# iostr710 register map
Registers are 16-bit, access not given, no defined reset value unless marked. A register's access mark holds for its fields unless they carry their own. Addresses are absolute; registers are grouped by the start of their names; [hi:lo] are bit positions; {n}, {i} and the like mark numbered series; 'fields as' and 'values as' point back to an identical list.

## RTC
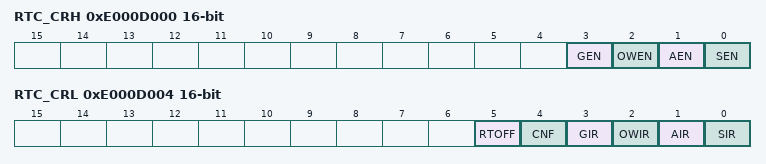
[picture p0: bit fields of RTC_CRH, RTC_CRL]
0xE000D000 RTC_CRH
  [3] GEN, [2] OWEN, [1] AEN, [0] SEN
0xE000D004 RTC_CRL
  [5] RTOFF, [4] CNF, [3] GIR, [2] OWIR, [1] AIR, [0] SIR
0xE000D008 RTC_PRLH
  [3:0] PRSL
0xE000D00C RTC_PRLL
0xE000D010 RTC_DIVH
  [3:0] RTCDIV
0xE000D014 RTC_DIVL
0xE000D018 RTC_CNTH
0xE000D01C RTC_CNTL
0xE000D020 RTC_ALRH
0xE000D024 RTC_ALRL

## WDG
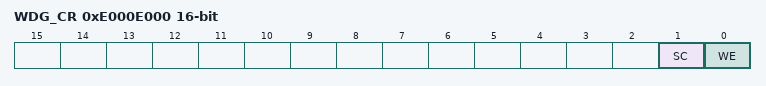
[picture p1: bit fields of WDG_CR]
0xE000E000 WDG_CR
  [1] SC, [0] WE
0xE000E004 WDG_PR
  [7:0] PR
0xE000E008 WDG_VR
0xE000E00C WDG_CNT
0xE000E010 WDG_SR
  [0] EC
0xE000E014 WDG_MR
  [0] ECM
0xE000E018 WDG_KR

## TIM0
0xE0009000 TIM0_ICAR
0xE0009004 TIM0_ICBR
0xE0009008 TIM0_OCAR
0xE000900C TIM0_OCBR
0xE0009010 TIM0_CNTR
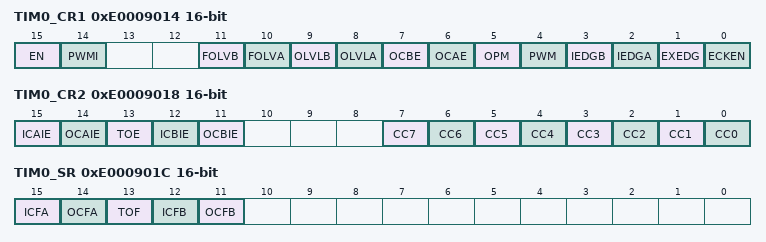
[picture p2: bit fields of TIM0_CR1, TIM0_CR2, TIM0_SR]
0xE0009014 TIM0_CR1
  [15] EN, [14] PWMI, [11] FOLVB, [10] FOLVA, [9] OLVLB, [8] OLVLA, [7] OCBE, [6] OCAE, [5] OPM, [4] PWM, [3] IEDGB, [2] IEDGA, [1] EXEDG, [0] ECKEN
0xE0009018 TIM0_CR2
  [15] ICAIE, [14] OCAIE, [13] TOE, [12] ICBIE, [11] OCBIE, [n] CC{n} (n=0..7)
0xE000901C TIM0_SR
  [15] ICFA, [14] OCFA, [13] TOF, [12] ICFB, [11] OCFB

## TIM1
0xE000A000 TIM1_ICAR
0xE000A004 TIM1_ICBR
0xE000A008 TIM1_OCAR
0xE000A00C TIM1_OCBR
0xE000A010 TIM1_CNTR
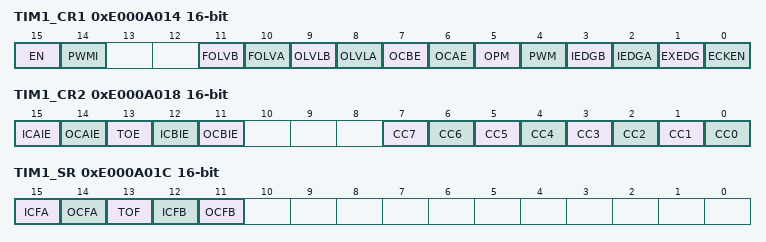
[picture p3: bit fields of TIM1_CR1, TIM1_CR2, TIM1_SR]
0xE000A014 TIM1_CR1
  [15] EN, [14] PWMI, [11] FOLVB, [10] FOLVA, [9] OLVLB, [8] OLVLA, [7] OCBE, [6] OCAE, [5] OPM, [4] PWM, [3] IEDGB, [2] IEDGA, [1] EXEDG, [0] ECKEN
0xE000A018 TIM1_CR2
  [15] ICAIE, [14] OCAIE, [13] TOE, [12] ICBIE, [11] OCBIE, [n] CC{n} (n=0..7)
0xE000A01C TIM1_SR
  [15] ICFA, [14] OCFA, [13] TOF, [12] ICFB, [11] OCFB

## TIM2
0xE000B000 TIM2_ICAR
0xE000B004 TIM2_ICBR
0xE000B008 TIM2_OCAR
0xE000B00C TIM2_OCBR
0xE000B010 TIM2_CNTR
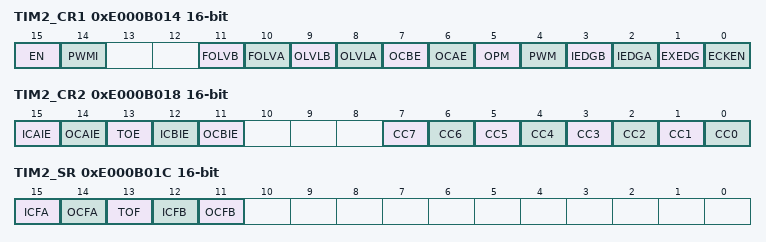
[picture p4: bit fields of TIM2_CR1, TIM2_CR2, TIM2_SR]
0xE000B014 TIM2_CR1
  [15] EN, [14] PWMI, [11] FOLVB, [10] FOLVA, [9] OLVLB, [8] OLVLA, [7] OCBE, [6] OCAE, [5] OPM, [4] PWM, [3] IEDGB, [2] IEDGA, [1] EXEDG, [0] ECKEN
0xE000B018 TIM2_CR2
  [15] ICAIE, [14] OCAIE, [13] TOE, [12] ICBIE, [11] OCBIE, [n] CC{n} (n=0..7)
0xE000B01C TIM2_SR
  [15] ICFA, [14] OCFA, [13] TOF, [12] ICFB, [11] OCFB

## TIM3
0xE000C000 TIM3_ICAR
0xE000C004 TIM3_ICBR
0xE000C008 TIM3_OCAR
0xE000C00C TIM3_OCBR
0xE000C010 TIM3_CNTR
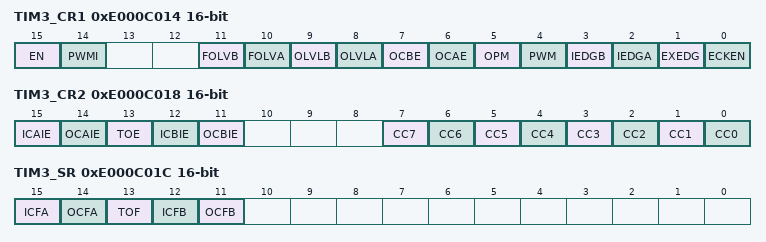
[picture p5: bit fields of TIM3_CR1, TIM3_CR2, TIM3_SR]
0xE000C014 TIM3_CR1
  [15] EN, [14] PWMI, [11] FOLVB, [10] FOLVA, [9] OLVLB, [8] OLVLA, [7] OCBE, [6] OCAE, [5] OPM, [4] PWM, [3] IEDGB, [2] IEDGA, [1] EXEDG, [0] ECKEN
0xE000C018 TIM3_CR2
  [15] ICAIE, [14] OCAIE, [13] TOE, [12] ICBIE, [11] OCBIE, [n] CC{n} (n=0..7)
0xE000C01C TIM3_SR
  [15] ICFA, [14] OCFA, [13] TOF, [12] ICFB, [11] OCFB

## CAN
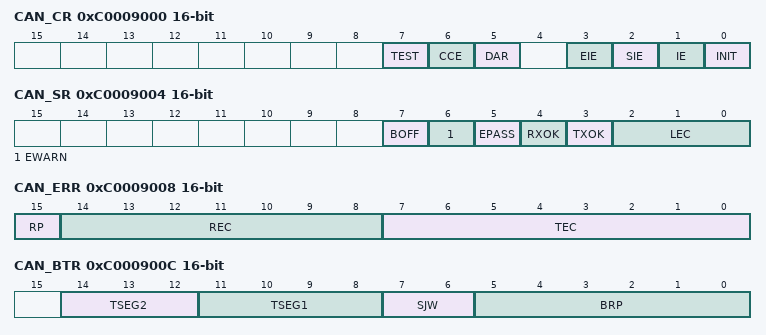
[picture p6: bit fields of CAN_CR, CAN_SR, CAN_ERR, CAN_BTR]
0xC0009000 CAN_CR
  [7] TEST, [6] CCE, [5] DAR, [3] EIE, [2] SIE, [1] IE, [0] INIT
0xC0009004 CAN_SR
  [7] BOFF, [6] EWARN, [5] EPASS, [4] RXOK, [3] TXOK, [2:0] LEC
0xC0009008 CAN_ERR
  [15] RP, [14:8] REC, [7:0] TEC
0xC000900C CAN_BTR
  [14:12] TSEG2, [11:8] TSEG1, [7:6] SJW, [5:0] BRP
0xC0009010 CAN_IDR
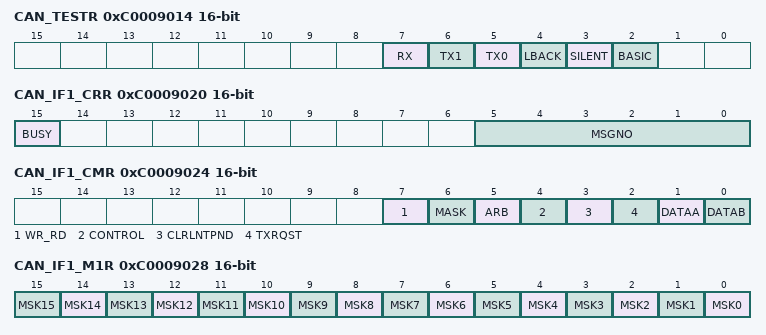
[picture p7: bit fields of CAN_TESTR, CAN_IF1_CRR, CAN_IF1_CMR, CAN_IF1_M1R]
0xC0009014 CAN_TESTR
  [7] RX, [6] TX1, [5] TX0, [4] LBACK, [3] SILENT, [2] BASIC
0xC0009018 CAN_BRPR
  [3:0] BRPE
0xC0009020 CAN_IF1_CRR
  [15] BUSY, [5:0] MSGNO
0xC0009024 CAN_IF1_CMR
  [7] WR_RD, [6] MASK, [5] ARB, [4] CONTROL, [3] CLRLNTPND, [2] TXRQST, [1] DATAA, [0] DATAB
0xC0009028 CAN_IF1_M1R
  [n] MSK{n} (n=0..15)
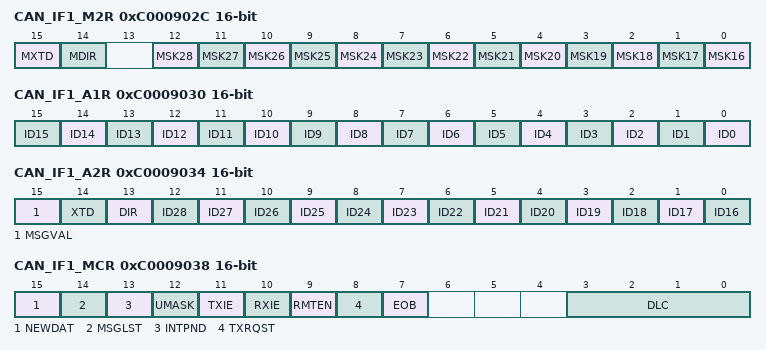
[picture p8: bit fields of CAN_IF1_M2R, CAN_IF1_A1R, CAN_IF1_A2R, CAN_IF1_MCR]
0xC000902C CAN_IF1_M2R
  [15] MXTD, [14] MDIR, [n-16] MSK{n} (n=16..28)
0xC0009030 CAN_IF1_A1R
  [n] ID{n} (n=0..15)
0xC0009034 CAN_IF1_A2R
  [15] MSGVAL, [14] XTD, [13] DIR, [n-16] ID{n} (n=16..28)
0xC0009038 CAN_IF1_MCR
  [15] NEWDAT, [14] MSGLST, [13] INTPND, [12] UMASK, [11] TXIE, [10] RXIE, [9] RMTEN, [8] TXRQST, [7] EOB, [3:0] DLC
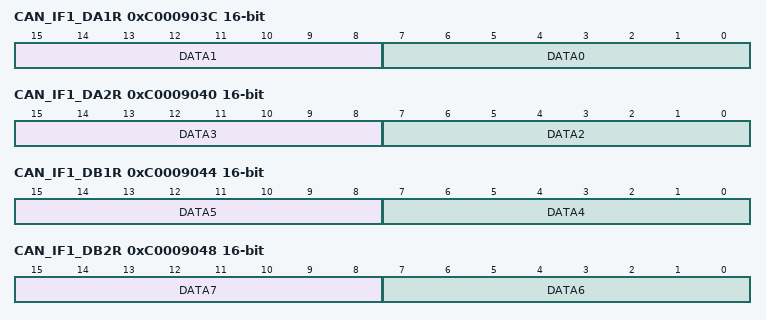
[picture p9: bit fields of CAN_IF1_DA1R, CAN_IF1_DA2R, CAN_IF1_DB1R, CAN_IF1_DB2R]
0xC000903C CAN_IF1_DA1R
  [15:8] DATA1, [7:0] DATA0
0xC0009040 CAN_IF1_DA2R
  [15:8] DATA3, [7:0] DATA2
0xC0009044 CAN_IF1_DB1R
  [15:8] DATA5, [7:0] DATA4
0xC0009048 CAN_IF1_DB2R
  [15:8] DATA7, [7:0] DATA6
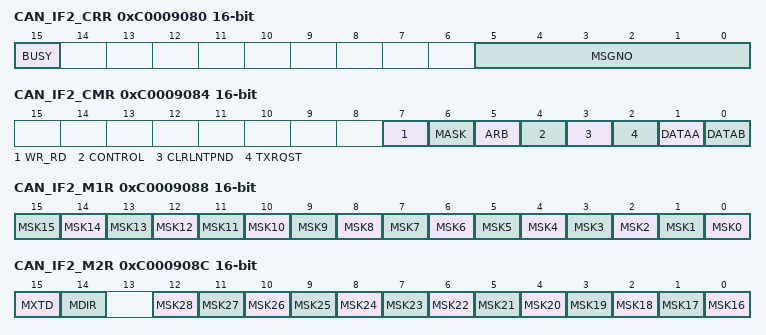
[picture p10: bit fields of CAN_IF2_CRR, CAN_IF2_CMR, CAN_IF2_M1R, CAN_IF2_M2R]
0xC0009080 CAN_IF2_CRR
  [15] BUSY, [5:0] MSGNO
0xC0009084 CAN_IF2_CMR
  fields as CAN_IF1_CMR
0xC0009088 CAN_IF2_M1R
  [n] MSK{n} (n=0..15)
0xC000908C CAN_IF2_M2R
  [15] MXTD, [14] MDIR, [n-16] MSK{n} (n=16..28)
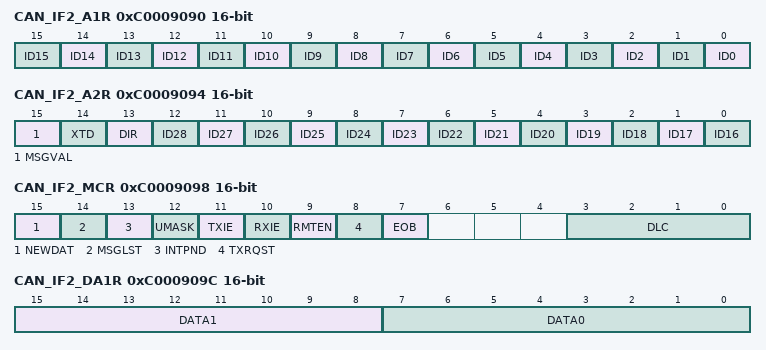
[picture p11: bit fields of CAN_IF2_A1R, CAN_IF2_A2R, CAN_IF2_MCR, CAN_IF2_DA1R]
0xC0009090 CAN_IF2_A1R
  [n] ID{n} (n=0..15)
0xC0009094 CAN_IF2_A2R
  [15] MSGVAL, [14] XTD, [13] DIR, [n-16] ID{n} (n=16..28)
0xC0009098 CAN_IF2_MCR
  fields as CAN_IF1_MCR
0xC000909C CAN_IF2_DA1R
  [15:8] DATA1, [7:0] DATA0
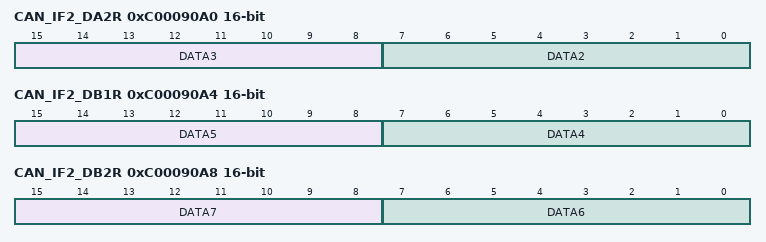
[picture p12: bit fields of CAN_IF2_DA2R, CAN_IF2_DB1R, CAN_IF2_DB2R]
0xC00090A0 CAN_IF2_DA2R
  [15:8] DATA3, [7:0] DATA2
0xC00090A4 CAN_IF2_DB1R
  [15:8] DATA5, [7:0] DATA4
0xC00090A8 CAN_IF2_DB2R
  [15:8] DATA7, [7:0] DATA6
0xC0009100 CAN_TXR1R 32-bit
0xC0009104 CAN_TXR2R 32-bit
0xC0009120 CAN_ND1R 32-bit
0xC0009124 CAN_ND2R 32-bit
0xC0009140 CAN_IP1R 32-bit
0xC0009144 CAN_IP2R 32-bit
0xC0009160 CAN_MV1R 32-bit
0xC0009164 CAN_MV2R 32-bit
